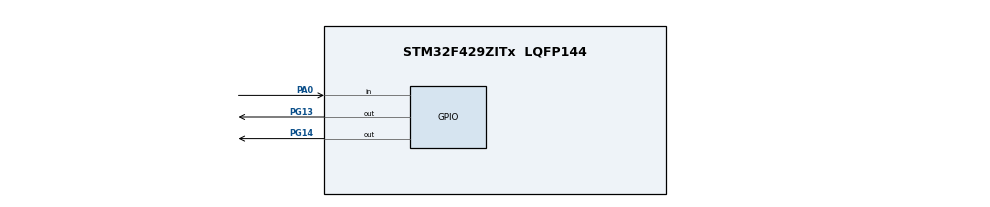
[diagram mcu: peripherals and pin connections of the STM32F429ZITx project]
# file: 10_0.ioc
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Mcu.Family=STM32F4
RCC.CortexFreq_Value=16000000
FREERTOS.Tasks01=defaultTask,24,128,StartDefaultTask,Default,NULL,Dynamic,NULL,NULL;PRG1,24,128,StartPRG1,Default,NULL,Dynamic,NULL,NULL;PRG2,24,128,StartPRG2,Default,NULL,Dynamic,NULL,NULL;PRG3,24,128,StartPRG3,Default,NULL,Dynamic,NULL,NULL;PRG4,24,128,StartPRG4,Default,NULL,Dynamic,NULL,NULL;PRG5,25,128,StartPRG5,Default,NULL,Dynamic,NULL,NULL;PRG6,25,128,StartPRG6,Default,NULL,Dynamic,NULL,NULL
PA0/WKUP.Signal=GPIO_Input
PG13.Signal=GPIO_Output
ProjectManager.StackSize=0x400
VP_FREERTOS_VS_CMSIS_V2.Mode=CMSIS_V2
PA13.Signal=SYS_JTMS-SWDIO
ProjectManager.TargetToolchain=EWARM V8.32
RCC.LSE_VALUE=32768
RCC.AHBFreq_Value=16000000
PG14.Signal=GPIO_Output
RCC.HSE_VALUE=25000000
PB3.Mode=JTAG_5_pins
board=custom
RCC.VCOOutputFreq_Value=192000000
PA15.Mode=JTAG_5_pins
RCC.APB2Freq_Value=16000000
PB4.Mode=JTAG_5_pins
PA14.Mode=JTAG_5_pins
VP_SYS_VS_tim1.Mode=TIM1
PA13.Mode=JTAG_5_pins
Mcu.Name=STM32F429ZITx
PB3.Signal=SYS_JTDO-SWO
RCC.SYSCLKFreq_VALUE=16000000
Mcu.Package=LQFP144
NVIC.TimeBase=TIM1_UP_TIM10_IRQn
NVIC.TimeBaseIP=TIM1
PA14.Signal=SYS_JTCK-SWCLK
PA15.Signal=SYS_JTDI
ProjectManager.HeapSize=0x200
NVIC.TIM1_UP_TIM10_IRQn=true\:0\:0\:false\:false\:true\:false\:false\:true
RCC.HSI_VALUE=16000000
NVIC.PriorityGroup=NVIC_PRIORITYGROUP_4
RCC.APB1Freq_Value=16000000
PB4.Signal=SYS_JTRST

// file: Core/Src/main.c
/* USER CODE BEGIN Header */
/**
  ******************************************************************************
  * @file           : main.c
  * @brief          : Main program body
  ******************************************************************************
  * @attention
  *
  * <h2><center>&copy; Copyright (c) 2020 STMicroelectronics.
  * All rights reserved.</center></h2>
  *
  * This software component is licensed by ST under Ultimate Liberty license
  * SLA0044, the "License"; You may not use this file except in compliance with
  * the License. You may obtain a copy of the License at:
  *                             www.st.com/SLA0044
  *
  ******************************************************************************
  */
/* USER CODE END Header */
#include "main.h"
#include "cmsis_os.h"

/* Definitions for defaultTask */
osThreadId_t defaultTaskHandle;
const osThreadAttr_t defaultTask_attributes = {
  .name = "defaultTask",
  .priority = (osPriority_t) osPriorityNormal2,
  .stack_size = 128 * 4
};
/* Definitions for PRG1 */
osThreadId_t PRG1Handle;
const osThreadAttr_t PRG1_attributes = {
  .name = "PRG1",
  .priority = (osPriority_t) osPriorityNormal,
  .stack_size = 128 * 4
};
/* Definitions for PRG2 */
osThreadId_t PRG2Handle;
const osThreadAttr_t PRG2_attributes = {
  .name = "PRG2",
  .priority = (osPriority_t) osPriorityNormal,
  .stack_size = 128 * 4
};
/* Definitions for PRG3 */
osThreadId_t PRG3Handle;
const osThreadAttr_t PRG3_attributes = {
  .name = "PRG3",
  .priority = (osPriority_t) osPriorityNormal,
  .stack_size = 128 * 4
};
/* Definitions for PRG4 */
osThreadId_t PRG4Handle;
const osThreadAttr_t PRG4_attributes = {
  .name = "PRG4",
  .priority = (osPriority_t) osPriorityNormal,
  .stack_size = 128 * 4
};
/* Definitions for PRG5 */
osThreadId_t PRG5Handle;
const osThreadAttr_t PRG5_attributes = {
  .name = "PRG5",
  .priority = (osPriority_t) osPriorityNormal1,
  .stack_size = 128 * 4
};
/* Definitions for PRG6 */
osThreadId_t PRG6Handle;
const osThreadAttr_t PRG6_attributes = {
  .name = "PRG6",
  .priority = (osPriority_t) osPriorityNormal1,
  .stack_size = 128 * 4
};

void SystemClock_Config(void);
static void MX_GPIO_Init(void);
void StartDefaultTask(void *argument);
void StartPRG1(void *argument);
void StartPRG2(void *argument);
void StartPRG3(void *argument);
void StartPRG4(void *argument);
void StartPRG5(void *argument);
void StartPRG6(void *argument);

/* USER CODE BEGIN 0 */

void suspendAllTasks() {
  LL_GPIO_ResetOutputPin(GPIOG, LL_GPIO_PIN_13);
  LL_GPIO_ResetOutputPin(GPIOG, LL_GPIO_PIN_14);
  vTaskSuspend(PRG1Handle);
  vTaskSuspend(PRG2Handle);
  vTaskSuspend(PRG3Handle);
  vTaskSuspend(PRG4Handle);
  vTaskSuspend(PRG5Handle);
  vTaskSuspend(PRG6Handle);

}

void delay(int counts) {
    for (volatile int i = 0; i < 16000; ++i) {
      for (volatile int j = 0; j < counts; ++j) {
        ;
      }
    }
}

/* USER CODE END 0 */

int main(void)
{

  /* MCU Configuration--------------------------------------------------------*/

  /* Reset of all peripherals, Initializes the Flash interface and the Systick. */
  HAL_Init();

  /* Configure the system clock */
  SystemClock_Config();

  /* Initialize all configured peripherals */
  MX_GPIO_Init();

  /* Init scheduler */
  osKernelInitialize();

  /* Create the thread(s) */
  /* creation of defaultTask */
  defaultTaskHandle = osThreadNew(StartDefaultTask, NULL, &defaultTask_attributes);

  /* creation of PRG1 */
  PRG1Handle = osThreadNew(StartPRG1, NULL, &PRG1_attributes);

  /* creation of PRG2 */
  PRG2Handle = osThreadNew(StartPRG2, NULL, &PRG2_attributes);

  /* creation of PRG3 */
  PRG3Handle = osThreadNew(StartPRG3, NULL, &PRG3_attributes);

  /* creation of PRG4 */
  PRG4Handle = osThreadNew(StartPRG4, NULL, &PRG4_attributes);

  /* creation of PRG5 */
  PRG5Handle = osThreadNew(StartPRG5, NULL, &PRG5_attributes);

  /* creation of PRG6 */
  PRG6Handle = osThreadNew(StartPRG6, NULL, &PRG6_attributes);

  suspendAllTasks();
  /* Start scheduler */
  osKernelStart();

  /* We should never get here as control is now taken by the scheduler */
  /* Infinite loop */
  while (1)
  {

  }
}

void SystemClock_Config(void)
{
  LL_FLASH_SetLatency(LL_FLASH_LATENCY_0);
  while(LL_FLASH_GetLatency()!= LL_FLASH_LATENCY_0)
  {
  }
  LL_PWR_SetRegulVoltageScaling(LL_PWR_REGU_VOLTAGE_SCALE3);
  LL_PWR_DisableOverDriveMode();
  LL_RCC_HSI_SetCalibTrimming(16);
  LL_RCC_HSI_Enable();

   /* Wait till HSI is ready */
  while(LL_RCC_HSI_IsReady() != 1)
  {

  }
  LL_RCC_SetAHBPrescaler(LL_RCC_SYSCLK_DIV_1);
  LL_RCC_SetAPB1Prescaler(LL_RCC_APB1_DIV_1);
  LL_RCC_SetAPB2Prescaler(LL_RCC_APB2_DIV_1);
  LL_RCC_SetSysClkSource(LL_RCC_SYS_CLKSOURCE_HSI);

   /* Wait till System clock is ready */
  while(LL_RCC_GetSysClkSource() != LL_RCC_SYS_CLKSOURCE_STATUS_HSI)
  {

  }
  LL_SetSystemCoreClock(16000000);

   /* Update the time base */
  if (HAL_InitTick (TICK_INT_PRIORITY) != HAL_OK)
  {
    Error_Handler();
  }
  LL_RCC_SetTIMPrescaler(LL_RCC_TIM_PRESCALER_TWICE);
}

static void MX_GPIO_Init(void)
{
  LL_GPIO_InitTypeDef GPIO_InitStruct = {0};

  /* GPIO Ports Clock Enable */
  LL_AHB1_GRP1_EnableClock(LL_AHB1_GRP1_PERIPH_GPIOA);
  LL_AHB1_GRP1_EnableClock(LL_AHB1_GRP1_PERIPH_GPIOG);
  LL_AHB1_GRP1_EnableClock(LL_AHB1_GRP1_PERIPH_GPIOB);

  /**/
  LL_GPIO_ResetOutputPin(GPIOG, LL_GPIO_PIN_13|LL_GPIO_PIN_14);

  /**/
  GPIO_InitStruct.Pin = LL_GPIO_PIN_0;
  GPIO_InitStruct.Mode = LL_GPIO_MODE_INPUT;
  GPIO_InitStruct.Pull = LL_GPIO_PULL_NO;
  LL_GPIO_Init(GPIOA, &GPIO_InitStruct);

  /**/
  GPIO_InitStruct.Pin = LL_GPIO_PIN_13|LL_GPIO_PIN_14;
  GPIO_InitStruct.Mode = LL_GPIO_MODE_OUTPUT;
  GPIO_InitStruct.Speed = LL_GPIO_SPEED_FREQ_LOW;
  GPIO_InitStruct.OutputType = LL_GPIO_OUTPUT_PUSHPULL;
  GPIO_InitStruct.Pull = LL_GPIO_PULL_NO;
  LL_GPIO_Init(GPIOG, &GPIO_InitStruct);

}

void StartDefaultTask(void *argument)
{
  /* USER CODE BEGIN 5 */
  int mode = 0;
  suspendAllTasks();
  /* Infinite loop */
  for(;;)
  {
    if (LL_GPIO_IsInputPinSet(GPIOA, LL_GPIO_PIN_0)) {
      osDelay(100);
      if (LL_GPIO_IsInputPinSet(GPIOA, LL_GPIO_PIN_0)) {
        ++mode;
        if (mode > 4)
          mode = 0;
        suspendAllTasks();
        switch(mode) {
          case 0:
            suspendAllTasks();
            break;
          case 1:
            suspendAllTasks();
            vTaskResume(PRG1Handle);
            vTaskResume(PRG2Handle);
            break;
          case 2:
            suspendAllTasks();
            vTaskResume(PRG3Handle);
            vTaskResume(PRG4Handle);
            break;
          case 3:
            suspendAllTasks();
            vTaskResume(PRG1Handle);
            vTaskResume(PRG5Handle);
            break;
          case 4:
            suspendAllTasks();
            vTaskResume(PRG3Handle);
            vTaskResume(PRG6Handle);
            break;
          default:
            suspendAllTasks();
            break;
        }
      }
    }
    osDelay(1);
  }
  /* USER CODE END 5 */
}

void StartPRG1(void *argument)
{
  /* USER CODE BEGIN StartPRG1 */
  /* Infinite loop */
  for(;;)
  {
    LL_GPIO_ResetOutputPin(GPIOG, LL_GPIO_PIN_13);
    osDelay(500);
    LL_GPIO_SetOutputPin(GPIOG, LL_GPIO_PIN_13);
    osDelay(500);
  }
  /* USER CODE END StartPRG1 */
}

void StartPRG2(void *argument)
{
  /* USER CODE BEGIN StartPRG2 */
  /* Infinite loop */
  for(;;)
  {
    LL_GPIO_ResetOutputPin(GPIOG, LL_GPIO_PIN_14);
    osDelay(1000);
    LL_GPIO_SetOutputPin(GPIOG, LL_GPIO_PIN_14);
    osDelay(1000);
  }
  /* USER CODE END StartPRG2 */
}

void StartPRG3(void *argument)
{
  /* USER CODE BEGIN StartPRG3 */
  /* Infinite loop */
  for(;;)
  {
    LL_GPIO_ResetOutputPin(GPIOG, LL_GPIO_PIN_13);
    delay(50);
    LL_GPIO_SetOutputPin(GPIOG, LL_GPIO_PIN_13);
    delay(50);
  }
  /* USER CODE END StartPRG3 */
}

void StartPRG4(void *argument)
{
  /* USER CODE BEGIN StartPRG4 */
  /* Infinite loop */
  for(;;)
  {
    LL_GPIO_ResetOutputPin(GPIOG, LL_GPIO_PIN_14);
    delay(100);
    LL_GPIO_SetOutputPin(GPIOG, LL_GPIO_PIN_14);
    delay(100);
  }
  /* USER CODE END StartPRG4 */
}

void StartPRG5(void *argument)
{
  /* USER CODE BEGIN StartPRG5 */
  /* Infinite loop */
  for(;;)
  {
    LL_GPIO_ResetOutputPin(GPIOG, LL_GPIO_PIN_14);
    osDelay(1000);
    LL_GPIO_SetOutputPin(GPIOG, LL_GPIO_PIN_14);
    osDelay(1000);
  }
  /* USER CODE END StartPRG5 */
}

void StartPRG6(void *argument)
{
  /* USER CODE BEGIN StartPRG6 */
  /* Infinite loop */
  for(;;)
  {
    LL_GPIO_ResetOutputPin(GPIOG, LL_GPIO_PIN_14);
    delay(100);
    LL_GPIO_SetOutputPin(GPIOG, LL_GPIO_PIN_14);
    delay(100);
  }
  /* USER CODE END StartPRG6 */
}

void HAL_TIM_PeriodElapsedCallback(TIM_HandleTypeDef *htim)
{
  if (htim->Instance == TIM1) {
    HAL_IncTick();
  }
}

void Error_Handler(void)
{
}

/************************ (C) COPYRIGHT STMicroelectronics *****END OF FILE****/
